# InterruptDemo register map
File version: 1.0
Registers are access not given, no defined reset value unless marked. A register's access mark holds for its fields unless they carry their own. Offsets are from the block's base; lines under a group give offsets from that group; [hi:lo] are bit positions; {n}, {i} and the like mark numbered series; 'fields as' and 'values as' point back to an identical list; <NAME> marks a mode.

## Memory map
0x40000000 IRQ

## IRQ
Base 0x40000000
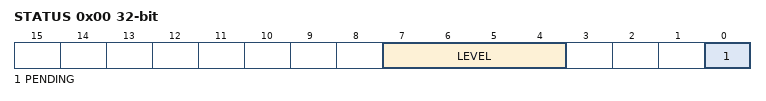
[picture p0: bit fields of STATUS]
0x00 STATUS read-clears
  [7:4] LEVEL range 0..7, [0] PENDING write-1-clears
